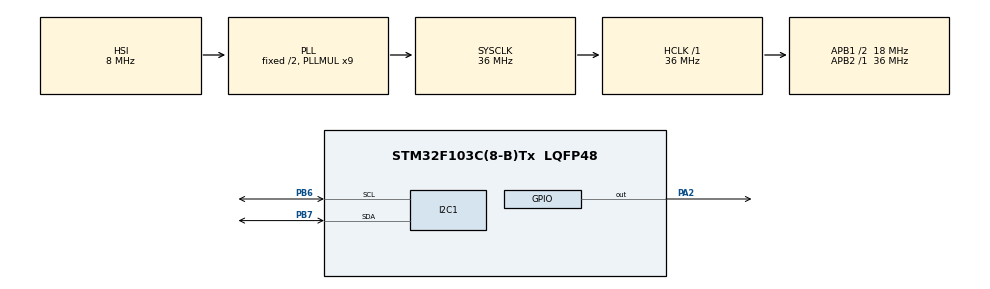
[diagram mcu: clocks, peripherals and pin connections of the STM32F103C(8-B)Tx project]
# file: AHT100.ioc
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I2C1.I2C_Mode=I2C_Fast
Mcu.Family=STM32F1
Mcu.Name=STM32F103C(8-B)Tx
Mcu.Package=LQFP48
NVIC.I2C1_EV_IRQn=true\:0\:0\:false\:false\:true\:true\:true\:true
NVIC.PriorityGroup=NVIC_PRIORITYGROUP_4
PA13.Mode=Serial_Wire
PA13.Signal=SYS_JTMS-SWDIO
PA14.Mode=Serial_Wire
PA14.Signal=SYS_JTCK-SWCLK
PA2.Signal=GPIO_Output
PB6.Mode=I2C
PB6.Signal=I2C1_SCL
PB7.Mode=I2C
PB7.Signal=I2C1_SDA
PD0-OSC_IN.Mode=HSE-External-Oscillator
PD0-OSC_IN.Signal=RCC_OSC_IN
PD1-OSC_OUT.Mode=HSE-External-Oscillator
PD1-OSC_OUT.Signal=RCC_OSC_OUT
ProjectManager.HeapSize=0x200
ProjectManager.StackSize=0x400
ProjectManager.TargetToolchain=STM32CubeIDE
RCC.AHBFreq_Value=36000000
RCC.APB1CLKDivider=RCC_HCLK_DIV2
RCC.APB1Freq_Value=18000000
RCC.APB1TimFreq_Value=36000000
RCC.APB2Freq_Value=36000000
RCC.APB2TimFreq_Value=36000000
RCC.HCLKFreq_Value=36000000
RCC.PLLMUL=RCC_PLL_MUL9
RCC.SYSCLKFreq_VALUE=36000000
RCC.SYSCLKSource=RCC_SYSCLKSOURCE_PLLCLK
RCC.USBFreq_Value=36000000
TIM2.AutoReloadPreload=TIM_AUTORELOAD_PRELOAD_ENABLE
TIM2.Period=999
TIM2.Prescaler=35999
TIM2.TIM_MasterOutputTrigger=TIM_TRGO_UPDATE
TIM4.Period=999
TIM4.Prescaler=799
VP_TIM2_VS_ClockSourceINT.Mode=Internal
VP_TIM4_VS_ClockSourceINT.Mode=Internal
board=custom

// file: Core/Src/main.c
/* USER CODE BEGIN Header */
/**
  ******************************************************************************
  * @file           : main.c
  * @brief          : Main program body
  ******************************************************************************
  * @attention
  *
  * <h2><center>&copy; Copyright (c) 2020 STMicroelectronics.
  * All rights reserved.</center></h2>
  *
  * This software component is licensed by ST under BSD 3-Clause license,
  * the "License"; You may not use this file except in compliance with the
  * License. You may obtain a copy of the License at:
  *                        opensource.org/licenses/BSD-3-Clause
  *
  ******************************************************************************
  */
/* USER CODE END Header */
#include "main.h"

I2C_HandleTypeDef hi2c1;

TIM_HandleTypeDef htim2;
TIM_HandleTypeDef htim4;

/* USER CODE BEGIN PV */

/* Variables for AHT10 */
/* Variables for AHT10 */
uint8_t AHT10_RX_Data[6];
uint32_t AHT10_ADC_Raw;
float AHT10_Temperature;
uint8_t AHT10_TmpHum_Cmd = 0xAC;
#define AHT10_Adress 0x38 << 1

/* USER CODE END PV */

void SystemClock_Config(void);
static void MX_GPIO_Init(void);
static void MX_I2C1_Init(void);
static void MX_TIM4_Init(void);
static void MX_TIM2_Init(void);

/* USER CODE BEGIN 0 */
int checkon=0;
void EXTI1_IRQHandler(void)
{
	if (EXTI->PR & (1<<1))    // If the PA1 triggered the interrupt
	{
		EXTI->PR |= (1<<1);
		if(checkon == 0)
		{
			checkon=1;
			HAL_TIM_Base_Start_IT(&htim2);
			HAL_GPIO_WritePin(GPIOA, GPIO_PIN_2, SET);
		}else
		{
			checkon=0;
			HAL_TIM_Base_Stop_IT(&htim2);
			HAL_GPIO_WritePin(GPIOA, GPIO_PIN_2, RESET);
		}
	}

}
void TIM2_IRQHandler(void)
{
	HAL_TIM_IRQHandler(&htim2);
}
int kontrol11 =0;
int al=0;
void HAL_TIM_PeriodElapsedCallback(TIM_HandleTypeDef* htim)
{
	kontrol11++;
	if(TIM2->CNT %100 == 0 && htim == &htim2)
	{
		if(al == 0)
		{
			al=1;
			HAL_I2C_Master_Transmit(&hi2c1, AHT10_Adress, &AHT10_TmpHum_Cmd, 1, 100);
			return;
		}else
		{
			al=0;
			HAL_I2C_Master_Receive(&hi2c1, AHT10_Adress, (uint8_t*)AHT10_RX_Data, 6, 100);
		}
		AHT10_ADC_Raw = (((uint32_t)AHT10_RX_Data[3] & 15) << 16) | ((uint32_t)AHT10_RX_Data[4] << 8) | AHT10_RX_Data[5];
		AHT10_Temperature = (float)(AHT10_ADC_Raw * 200.00 / 1048576.00) - 50.00;
		if(AHT10_Temperature <= 30)
		{
			checkon =0;
			HAL_TIM_Base_Stop_IT(&htim2);
			HAL_GPIO_WritePin(GPIOA, GPIO_PIN_2, RESET);
		}
	}
}

/* USER CODE END 0 */

int main(void)
{

  /* MCU Configuration--------------------------------------------------------*/

  /* Reset of all peripherals, Initializes the Flash interface and the Systick. */
  HAL_Init();

  /* Configure the system clock */
  SystemClock_Config();

  /* Initialize all configured peripherals */
  MX_GPIO_Init();
  MX_I2C1_Init();
  MX_TIM4_Init();
  MX_TIM2_Init();
  /* USER CODE BEGIN 2 */
  AFIO->EXTICR[0] &= ~(0xf<<4);
  EXTI->IMR |= (1<<1);
  EXTI->RTSR |= (1<<1);  // Enable Rising Edge Trigger for PA1
  EXTI->FTSR &= ~(1<<1);
  NVIC_SetPriority (EXTI1_IRQn, 1);  // Set Priority
  NVIC_EnableIRQ (EXTI1_IRQn);
  NVIC_SetPriority(TIM2_IRQn,2);
  NVIC_EnableIRQ(TIM2_IRQn);
	/* TIM4 Int. every 100ms */

  /* USER CODE END 2 */

  /* Infinite loop */
  while (1)
  {

  }
}

void SystemClock_Config(void)
{
  RCC_OscInitTypeDef RCC_OscInitStruct = {0};
  RCC_ClkInitTypeDef RCC_ClkInitStruct = {0};

  /** Initializes the RCC Oscillators according to the specified parameters
  * in the RCC_OscInitTypeDef structure.
  */
  RCC_OscInitStruct.OscillatorType = RCC_OSCILLATORTYPE_HSI;
  RCC_OscInitStruct.HSIState = RCC_HSI_ON;
  RCC_OscInitStruct.HSICalibrationValue = RCC_HSICALIBRATION_DEFAULT;
  RCC_OscInitStruct.PLL.PLLState = RCC_PLL_ON;
  RCC_OscInitStruct.PLL.PLLSource = RCC_PLLSOURCE_HSI_DIV2;
  RCC_OscInitStruct.PLL.PLLMUL = RCC_PLL_MUL9;
  if (HAL_RCC_OscConfig(&RCC_OscInitStruct) != HAL_OK)
  {
    Error_Handler();
  }

  /** Initializes the CPU, AHB and APB buses clocks
  */
  RCC_ClkInitStruct.ClockType = RCC_CLOCKTYPE_HCLK|RCC_CLOCKTYPE_SYSCLK
                              |RCC_CLOCKTYPE_PCLK1|RCC_CLOCKTYPE_PCLK2;
  RCC_ClkInitStruct.SYSCLKSource = RCC_SYSCLKSOURCE_PLLCLK;
  RCC_ClkInitStruct.AHBCLKDivider = RCC_SYSCLK_DIV1;
  RCC_ClkInitStruct.APB1CLKDivider = RCC_HCLK_DIV2;
  RCC_ClkInitStruct.APB2CLKDivider = RCC_HCLK_DIV1;

  if (HAL_RCC_ClockConfig(&RCC_ClkInitStruct, FLASH_LATENCY_1) != HAL_OK)
  {
    Error_Handler();
  }
}

static void MX_I2C1_Init(void)
{

  hi2c1.Instance = I2C1;
  hi2c1.Init.ClockSpeed = 400000;
  hi2c1.Init.DutyCycle = I2C_DUTYCYCLE_2;
  hi2c1.Init.OwnAddress1 = 0;
  hi2c1.Init.AddressingMode = I2C_ADDRESSINGMODE_7BIT;
  hi2c1.Init.DualAddressMode = I2C_DUALADDRESS_DISABLE;
  hi2c1.Init.OwnAddress2 = 0;
  hi2c1.Init.GeneralCallMode = I2C_GENERALCALL_DISABLE;
  hi2c1.Init.NoStretchMode = I2C_NOSTRETCH_DISABLE;
  if (HAL_I2C_Init(&hi2c1) != HAL_OK)
  {
    Error_Handler();
  }

}

static void MX_TIM2_Init(void)
{

  TIM_ClockConfigTypeDef sClockSourceConfig = {0};
  TIM_MasterConfigTypeDef sMasterConfig = {0};

  htim2.Instance = TIM2;
  htim2.Init.Prescaler = 35999;
  htim2.Init.CounterMode = TIM_COUNTERMODE_UP;
  htim2.Init.Period = 999;
  htim2.Init.ClockDivision = TIM_CLOCKDIVISION_DIV1;
  htim2.Init.AutoReloadPreload = TIM_AUTORELOAD_PRELOAD_ENABLE;
  if (HAL_TIM_Base_Init(&htim2) != HAL_OK)
  {
    Error_Handler();
  }
  sClockSourceConfig.ClockSource = TIM_CLOCKSOURCE_INTERNAL;
  if (HAL_TIM_ConfigClockSource(&htim2, &sClockSourceConfig) != HAL_OK)
  {
    Error_Handler();
  }
  sMasterConfig.MasterOutputTrigger = TIM_TRGO_UPDATE;
  sMasterConfig.MasterSlaveMode = TIM_MASTERSLAVEMODE_DISABLE;
  if (HAL_TIMEx_MasterConfigSynchronization(&htim2, &sMasterConfig) != HAL_OK)
  {
    Error_Handler();
  }

}

static void MX_TIM4_Init(void)
{

  TIM_ClockConfigTypeDef sClockSourceConfig = {0};
  TIM_MasterConfigTypeDef sMasterConfig = {0};

  htim4.Instance = TIM4;
  htim4.Init.Prescaler = 799;
  htim4.Init.CounterMode = TIM_COUNTERMODE_UP;
  htim4.Init.Period = 999;
  htim4.Init.ClockDivision = TIM_CLOCKDIVISION_DIV1;
  htim4.Init.AutoReloadPreload = TIM_AUTORELOAD_PRELOAD_DISABLE;
  if (HAL_TIM_Base_Init(&htim4) != HAL_OK)
  {
    Error_Handler();
  }
  sClockSourceConfig.ClockSource = TIM_CLOCKSOURCE_INTERNAL;
  if (HAL_TIM_ConfigClockSource(&htim4, &sClockSourceConfig) != HAL_OK)
  {
    Error_Handler();
  }
  sMasterConfig.MasterOutputTrigger = TIM_TRGO_RESET;
  sMasterConfig.MasterSlaveMode = TIM_MASTERSLAVEMODE_DISABLE;
  if (HAL_TIMEx_MasterConfigSynchronization(&htim4, &sMasterConfig) != HAL_OK)
  {
    Error_Handler();
  }

}

static void MX_GPIO_Init(void)
{
  GPIO_InitTypeDef GPIO_InitStruct = {0};

  /* GPIO Ports Clock Enable */
  __HAL_RCC_GPIOD_CLK_ENABLE();
  __HAL_RCC_GPIOA_CLK_ENABLE();
  __HAL_RCC_GPIOB_CLK_ENABLE();

  /*Configure GPIO pin Output Level */
  HAL_GPIO_WritePin(GPIOA, GPIO_PIN_2, GPIO_PIN_RESET);

  /*Configure GPIO pin : PA2 */
  GPIO_InitStruct.Pin = GPIO_PIN_2;
  GPIO_InitStruct.Mode = GPIO_MODE_OUTPUT_PP;
  GPIO_InitStruct.Pull = GPIO_NOPULL;
  GPIO_InitStruct.Speed = GPIO_SPEED_FREQ_LOW;
  HAL_GPIO_Init(GPIOA, &GPIO_InitStruct);

}

void Error_Handler(void)
{
}
